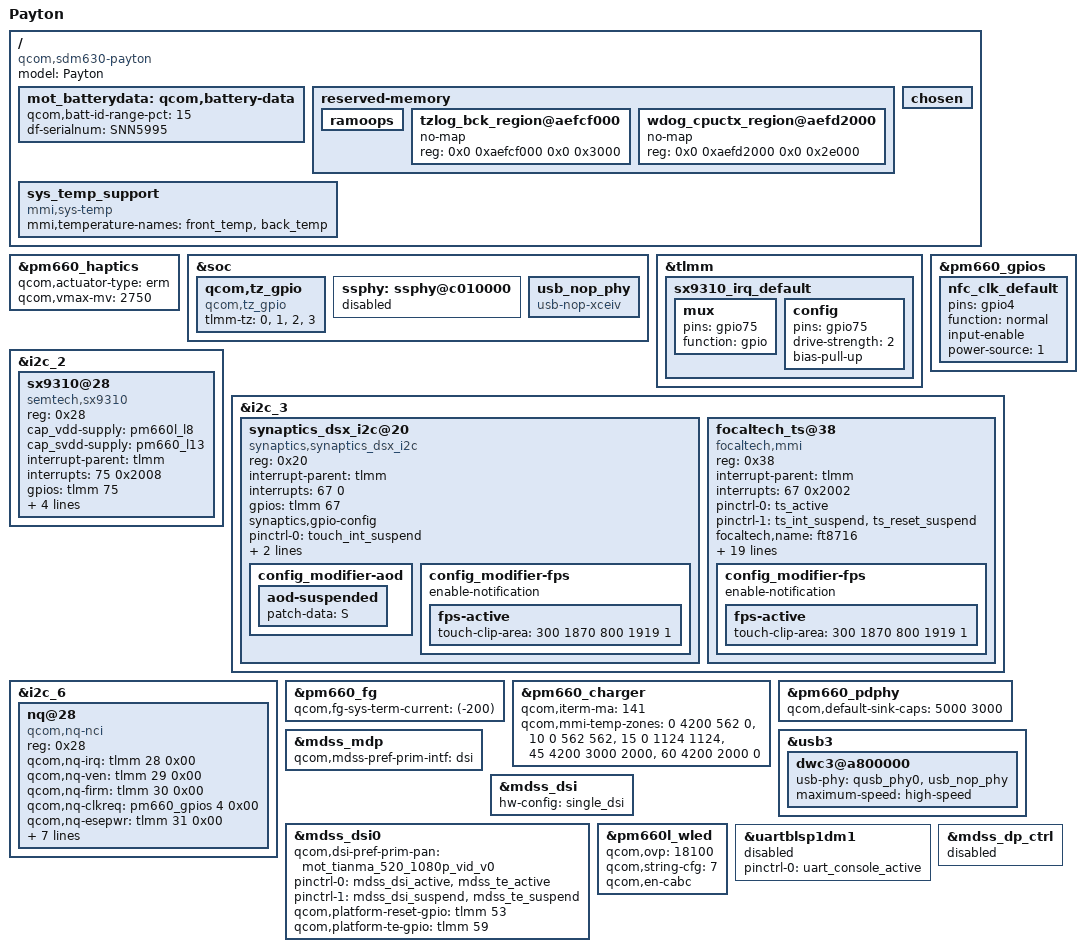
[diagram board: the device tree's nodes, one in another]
// Common device tree for the Moto X4 (payton).
// Board revisions (p1a/p2a/p2b) live in sdm630-payton-*.dts.

// Include required dtsi
#include "../../sdm630.dtsi"
#include "../moto-common.dtsi"
#include "../external-codec.dtsi"
#include "audio.dtsi"
#include "sdm630-camera-sensor-mot-payton.dtsi"
#include "dsi-panel-mot-tianma-520-1080p-vid.dtsi"
#include "dsi-panel-mot-boe-520-1080p-vid.dtsi"

/ {
	model = "Payton";
	compatible = "qcom,sdm630-payton", "qcom,sdm630-moto",
			"qcom,sdm630";
	// Battery
	mot_batterydata: qcom,battery-data {
		qcom,batt-id-range-pct = <15>;
		df-serialnum = "SNN5995";

		#include "fg-gen3-batterydata-hx40sunwoda-3000mah.dtsi"
		#include "fg-gen3-batterydata-hx40scud-3000mah.dtsi"
	};
	/delete-node/ firmware;

	// ramoops: same layout as the 4.4 kernel (no ECC), so the logs of a
	// failed boot can be read from a 4.4 based recovery
	reserved-memory {
		ramoops {
			/delete-property/ ecc-size;
			/*
			 * Keep the default write-combined mapping: "unbuffered"
			 * maps it as Device memory, and the unaligned stores of
			 * copy_from_user() into the pmsg zone then fault.
			 */
		};

		// Written by TrustZone (backup of its log and the CPU
		// contexts on a watchdog bite), reserved like on 4.4.
		tzlog_bck_region@aefcf000 {
			no-map;
			reg = <0x0 0xaefcf000 0x0 0x3000>;
		};

		wdog_cpuctx_region@aefd2000 {
			no-map;
			reg = <0x0 0xaefd2000 0x0 0x2e000>;
		};
	};

	// Surface temperatures computed by thermal-engine (sys_temp)
	sys_temp_support {
		compatible = "mmi,sys-temp";
		mmi,temperature-names = "front_temp",
					"back_temp";
		status = "ok";
	};
};

// Vibrator
&pm660_haptics {
	qcom,actuator-type = "erm";
	qcom,vmax-mv = <2750>;
};

&soc {
	// Protected GPIOs
	qcom,tz_gpio {
		compatible = "qcom,tz_gpio";
		tlmm-tz = <0>,
			<1>,
			<2>,
			<3>;
	};

	ssphy: ssphy@c010000 {
		status = "disabled";
	};

	usb_nop_phy: usb_nop_phy {
		compatible = "usb-nop-xceiv";
	};
};

// Pinctrl
&tlmm {
	sx9310_irq_default: sx9310_irq_default {
		mux {
			pins = "gpio75";
			function = "gpio";
		};

		config {
			pins = "gpio75";
			drive-strength = <2>;
			bias-pull-up;
		};
	};
};

&pm660_gpios {
	nfc_clk_default: nfc_clk_default {
		pins = "gpio4";
		function = "normal";
		input-enable;
		power-source = <1>;
	};
};

// SAR sensor
&i2c_2 { /* BLSP1 QUP2 */
	status = "okay";
	sx9310@28 {
		compatible = "semtech,sx9310";
		reg = <0x28>;
		cap_vdd-supply = <&pm660l_l8>;
		cap_svdd-supply = <&pm660_l13>;
		interrupt-parent = <&tlmm>;
		interrupts = <75 0x2008>;
		gpios = <&tlmm 75 0x2008>; /* IRQ */
		pinctrl-names = "default";
		pinctrl-0 = <&sx9310_irq_default>;
		reg_array_len = <6>;
		reg_array_val = <0x10 0x24 0x12 0x0B 0x13 0x03
			0x15 0xCA 0x19 0x20 0x30 0x02>;
	};
};

// Touchscreen: Synaptics (tianma panel) or Focaltech FT8716 (boe panel)
&i2c_3 { /* BLSP1 QUP3 */
	status = "okay";

	synaptics_dsx_i2c@20 {
		compatible = "synaptics,synaptics_dsx_i2c";
		reg = <0x20>;
		interrupt-parent = <&tlmm>;
		interrupts = <67 0>;
		gpios = <&tlmm 67 0>; /* IRQ */
		synaptics,gpio-config;
		pinctrl-names = "default", "active";
		pinctrl-0 = <&touch_int_suspend>;
		pinctrl-1 = <&touch_int_active>;
		config_modifier-names = "aod", "fps";
		config_modifier-aod {
			aod-suspended {
				/* Power->sleep; */
				patch-data = "S";
			};
		};
		config_modifier-fps {
			enable-notification;
			fps-active {
				touch-clip-area = <300 1870 800 1919 1>;
			};
		};
	};

	focaltech_ts@38 {
		compatible = "focaltech,mmi";
		reg = <0x38>;
		interrupt-parent = <&tlmm>;
		interrupts = <67 0x2002>;
		pinctrl-names = "pmx_ts_active", "pmx_ts_suspend";
		pinctrl-0 = <&ts_active>;
		pinctrl-1 = <&ts_int_suspend &ts_reset_suspend>;
		focaltech,name = "ft8716";
		focaltech,family-id = <0x87>;
		focaltech,reset-gpio = <&tlmm 66 0x00>;
		focaltech,irq-gpio = <&tlmm 67 0x2008>;
		focaltech,display-coords = <0 0 1080 1920>;
		focaltech,panel-coords = <0 0 1080 1920>;
		focaltech,i2c-pull-up;
		focaltech,group-id = <1>;
		focaltech,hard-reset-delay-ms = <20>;
		focaltech,soft-reset-delay-ms = <200>;
		focaltech,num-max-touches = <10>;
		focaltech,fw-delay-aa-ms = <2>;
		focaltech,fw-delay-55-ms = <2>;
		focaltech,fw-upgrade-id1 = <0x87>;
		focaltech,fw-upgrade-id2 = <0xA6>;
		focaltech,fw-delay-readid-ms = <20>;
		focaltech,fw-delay-era-flsh-ms = <2000>;
		focaltech,resume-in-workqueue;
		focaltech,ignore-id-check;
		config_modifier-names = "fps";
		config_modifier-fps {
			enable-notification;
			fps-active {
				touch-clip-area = <300 1870 800 1919 1>;
			};
		};
	};
};

// NFC
&i2c_6 { /* BLSP1 QUP6 */
	status = "okay";
	nq@28 {
		compatible = "qcom,nq-nci";
		reg = <0x28>;
		qcom,nq-irq = <&tlmm 28 0x00>;
		qcom,nq-ven = <&tlmm 29 0x00>;
		qcom,nq-firm = <&tlmm 30 0x00>;
		qcom,nq-clkreq = <&pm660_gpios 4 0x00>;
		qcom,nq-esepwr = <&tlmm 31 0x00>;
		interrupt-parent = <&tlmm>;
		qcom,clk-src = "BBCLK3";
		interrupts = <28 0>;
		interrupt-names = "nfc_irq";
		pinctrl-names = "nfc_active", "nfc_suspend";
		pinctrl-0 = <&nfc_int_active &nfc_enable_active
				&nfc_clk_default>;
		pinctrl-1 = <&nfc_int_suspend &nfc_enable_suspend>;
		clocks = <&clock_rpmcc RPM_SMD_LN_BB_CLK3>;
		clock-names = "ref_clk";
	};
};

// Charger
&pm660_fg {
	qcom,fg-sys-term-current = <(-200)>;
};

&pm660_charger {
	qcom,iterm-ma = <141>;
	qcom,mmi-temp-zones = <0 4200 562 0>,
				<10 0 562 562>,
				<15 0 1124 1124>,
				<45 4200 3000 2000>,
				<60 4200 2000 0>;
};

&pm660_pdphy {
	qcom,default-sink-caps = <5000 3000>; /* 5V @ 3A */
};

// USB
&usb3 {
	dwc3@a800000 {
		usb-phy = <&qusb_phy0>, <&usb_nop_phy>;
		maximum-speed = "high-speed";
	};
};

// Display configuration
&mdss_mdp {
	qcom,mdss-pref-prim-intf = "dsi";
};

&mdss_dsi {
	hw-config = "single_dsi";
};

&mdss_dsi0 {
	qcom,dsi-pref-prim-pan = <&mot_tianma_520_1080p_vid_v0>;
	pinctrl-names = "mdss_default", "mdss_sleep";
	pinctrl-0 = <&mdss_dsi_active &mdss_te_active>;
	pinctrl-1 = <&mdss_dsi_suspend &mdss_te_suspend>;
	qcom,platform-reset-gpio = <&tlmm 53 0>;
	qcom,platform-te-gpio = <&tlmm 59 0>;
};

&pm660l_wled {
	qcom,ovp = <18100>;
	qcom,string-cfg = <7>;	/* strings 1-3 (bitmask) */
	qcom,en-cabc;
	/delete-property/ qcom,auto-calibration;
};

// Debug UART (BLSP1 UART2, gpio4/5), console/earlycon only when requested
// on the kernel command line. sdm630.dtsi points stdout-path at it, which
// registers it as a console on its own: at 115200 baud, console_unlock()
// then never catches up with the boot log and holds console_lock, which
// blocks the framebuffer unblank in the composer.
/ {
	chosen {
		/delete-property/ stdout-path;
	};
};

/*
 * Keep the debug UART driver off. With no console= on the command line the
 * kernel makes the first tty console that registers the default console,
 * and msm_console_setup() holds a clock vote that is never dropped: the
 * BLSP1 UART2 clock then keeps GPLL0 and the CXO sleep vote up, so the SoC
 * never reaches XO shutdown. TARGET_PAYTON_UART_LOG logs through earlycon,
 * which doesn't need this node.
 */
&uartblsp1dm1 {
	status = "disabled";
	pinctrl-names = "default";
	pinctrl-0 = <&uart_console_active>;
};

&mdss_dp_ctrl{
	status = "disabled";
};
